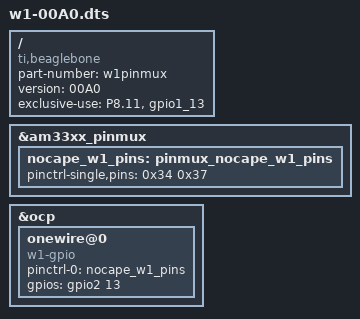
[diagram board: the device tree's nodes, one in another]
 /*
  * Copyright (C) 2012 Texas Instruments Incorporated - http://www.ti.com/
  *
  * This program is free software; you can redistribute it and/or modify
  * it under the terms of the GNU General Public License version 2 as
  * published by the Free Software Foundation.
  * Uses P8/Pin11?
  * Compile:
  * dtc -@ -O dtb -I dts -o /lib/firmware/w1-00A0.dtbo w1-00A0.dts 
  * Load:
  * echo w1 > /sys/devices/bone_capemgr.9/slots 
  */
  /dts-v1/;
  /plugin/;

  / {
         compatible = "ti,beaglebone","ti,beaglebone-black";
         part-number = "w1pinmux";
         version = "00A0";

/* state the resources this cape uses */
	exclusive-use =
		/* the pin header uses */
		"P8.11",	/* gpio1_13 */
		/* the hardware IP uses */
		"gpio1_13";

         fragment@0 {
                 target = <&am33xx_pinmux>;
                 __overlay__ {
                          nocape_w1_pins: pinmux_nocape_w1_pins {
                                  pinctrl-single,pins = <
                                          0x34 0x37       /* gpmc_ad13.gpio1_13, OMAP_PIN_INPUT_PULLUP | OMAP_MUX_MODE7 - w1-gpio */
                                  >;
                          };
                 };
         };

         fragment@1 {
                 target = <&ocp>;
                 __overlay__ {
                         onewire@0 {
                                 compatible      = "w1-gpio";
                                 pinctrl-names   = "default";
                                 pinctrl-0       = <&nocape_w1_pins>;
                                 status          = "okay";
                                 gpios = <&gpio2 13 0>;
                         };
                 };
         };
  };

